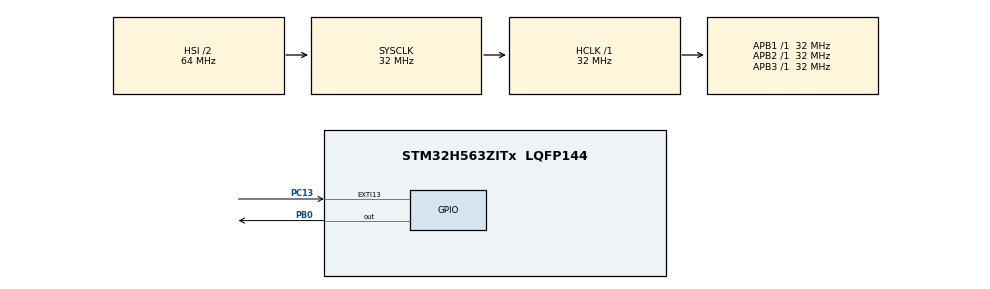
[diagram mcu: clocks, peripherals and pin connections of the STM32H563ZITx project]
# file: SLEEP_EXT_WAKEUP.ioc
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CORTEX_M33_NS.userName=CORTEX_M33
Mcu.Family=STM32H5
Mcu.Name=STM32H563ZITx
Mcu.Package=LQFP144
NVIC.EXTI13_IRQn=true\:0\:0\:false\:false\:true\:true\:true\:true
NVIC.PriorityGroup=NVIC_PRIORITYGROUP_4
NVIC.TIM3_IRQn=true\:0\:0\:false\:false\:true\:true\:true\:true
PB0.Signal=GPIO_Output
PC13.Signal=GPXTI13
PH0-OSC_IN(PH0).Mode=HSE-External-Oscillator
PH0-OSC_IN(PH0).Signal=RCC_OSC_IN
PH1-OSC_OUT(PH1).Mode=HSE-External-Oscillator
PH1-OSC_OUT(PH1).Signal=RCC_OSC_OUT
ProjectManager.HeapSize=0x200
ProjectManager.StackSize=0x400
ProjectManager.TargetToolchain=STM32CubeIDE
RCC.ADCFreq_Value=32000000
RCC.AHBFreq_Value=32000000
RCC.APB1Freq_Value=32000000
RCC.APB1TimFreq_Value=32000000
RCC.APB2Freq_Value=32000000
RCC.APB2TimFreq_Value=32000000
RCC.APB3Freq_Value=32000000
RCC.CSI_VALUE=4000000
RCC.CortexFreq_Value=32000000
RCC.EPOD_VALUE=4000000
RCC.HCLKFreq_Value=32000000
RCC.HSE_VALUE=25000000
RCC.HSI48_VALUE=48000000
RCC.HSI_VALUE=64000000
RCC.LSE_VALUE=32768
RCC.LSIRC_VALUE=32000
RCC.PLL2FRACN=0
RCC.PLL3FRACN=0
RCC.PLLFRACN=0
RCC.SYSCLKFreq_VALUE=32000000
RCC.USBFreq_Value=48000000
RCC.VCOOutputFreq_Value=516000000
VP_BOOTPATH_VS_BOOTPATH.Mode=BP_Activate
VP_CORTEX_M33_NS_VS_Hclk.Mode=Hclk_Mode
VP_MEMORYMAP_VS_MEMORYMAP.Mode=CurAppReg
VP_PWR_VS_DBSignals.Mode=DisableDeadBatterySignals
VP_PWR_VS_LPOM.Mode=PowerOptimisation
VP_PWR_VS_SECSignals.Mode=Security/Privilege
VP_TIM3_VS_ClockSourceINT.Mode=Internal
board=custom

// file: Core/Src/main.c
/* USER CODE BEGIN Header */
/**
  ******************************************************************************
  * @file           : main.c
  * @brief          : Main program body
  ******************************************************************************
  * @attention
  *
  * Copyright (c) 2024 STMicroelectronics.
  * All rights reserved.
  *
  * This software is licensed under terms that can be found in the LICENSE file
  * in the root directory of this software component.
  * If no LICENSE file comes with this software, it is provided AS-IS.
  *
  ******************************************************************************
  */
/* USER CODE END Header */
#include "main.h"

TIM_HandleTypeDef htim3;

/* USER CODE BEGIN PV */
uint8_t count =0;
/* USER CODE END PV */

void SystemClock_Config(void);
static void MX_GPIO_Init(void);
static void MX_TIM3_Init(void);

int main(void)
{

  /* MCU Configuration--------------------------------------------------------*/

  /* Reset of all peripherals, Initializes the Flash interface and the Systick. */
  HAL_Init();

  /* Configure the system clock */
  SystemClock_Config();

  /* Initialize all configured peripherals */
  MX_GPIO_Init();
  MX_TIM3_Init();

  /* Infinite loop */
  /* USER CODE BEGIN WHILE */
  while (1)

  {
	  if(count == 600)//60*10 10 minutes of inactivity counter
	  {
		  HAL_SuspendTick();// suspending systick clock before sleep low power

		  HAL_PWR_EnableSleepOnExit ();
		  //sleep mode
		  HAL_PWR_EnterSLEEPMode(PWR_MAINREGULATOR_ON, PWR_SLEEPENTRY_WFI);//entering sleep mode with wake up on external interrupt.

	  }
    /* USER CODE END WHILE */

  }
}

void SystemClock_Config(void)
{
  RCC_OscInitTypeDef RCC_OscInitStruct = {0};
  RCC_ClkInitTypeDef RCC_ClkInitStruct = {0};

  /** Configure the main internal regulator output voltage
  */
  __HAL_PWR_VOLTAGESCALING_CONFIG(PWR_REGULATOR_VOLTAGE_SCALE3);

  while(!__HAL_PWR_GET_FLAG(PWR_FLAG_VOSRDY)) {}

  /** Initializes the RCC Oscillators according to the specified parameters
  * in the RCC_OscInitTypeDef structure.
  */
  RCC_OscInitStruct.OscillatorType = RCC_OSCILLATORTYPE_HSI;
  RCC_OscInitStruct.HSIState = RCC_HSI_ON;
  RCC_OscInitStruct.HSIDiv = RCC_HSI_DIV2;
  RCC_OscInitStruct.HSICalibrationValue = RCC_HSICALIBRATION_DEFAULT;
  RCC_OscInitStruct.PLL.PLLState = RCC_PLL_NONE;
  if (HAL_RCC_OscConfig(&RCC_OscInitStruct) != HAL_OK)
  {
    Error_Handler();
  }

  /** Initializes the CPU, AHB and APB buses clocks
  */
  RCC_ClkInitStruct.ClockType = RCC_CLOCKTYPE_HCLK|RCC_CLOCKTYPE_SYSCLK
                              |RCC_CLOCKTYPE_PCLK1|RCC_CLOCKTYPE_PCLK2
                              |RCC_CLOCKTYPE_PCLK3;
  RCC_ClkInitStruct.SYSCLKSource = RCC_SYSCLKSOURCE_HSI;
  RCC_ClkInitStruct.AHBCLKDivider = RCC_SYSCLK_DIV1;
  RCC_ClkInitStruct.APB1CLKDivider = RCC_HCLK_DIV1;
  RCC_ClkInitStruct.APB2CLKDivider = RCC_HCLK_DIV1;
  RCC_ClkInitStruct.APB3CLKDivider = RCC_HCLK_DIV1;

  if (HAL_RCC_ClockConfig(&RCC_ClkInitStruct, FLASH_LATENCY_1) != HAL_OK)
  {
    Error_Handler();
  }

  /** Configure the programming delay
  */
  __HAL_FLASH_SET_PROGRAM_DELAY(FLASH_PROGRAMMING_DELAY_0);
}

static void MX_TIM3_Init(void)
{

  TIM_ClockConfigTypeDef sClockSourceConfig = {0};
  TIM_MasterConfigTypeDef sMasterConfig = {0};

  htim3.Instance = TIM3;
  htim3.Init.Prescaler = 10000;
  htim3.Init.CounterMode = TIM_COUNTERMODE_UP;
  htim3.Init.Period = 24999;//adjusted to give interupt every 1 sec
  htim3.Init.ClockDivision = TIM_CLOCKDIVISION_DIV1;
  htim3.Init.AutoReloadPreload = TIM_AUTORELOAD_PRELOAD_DISABLE;
  if (HAL_TIM_Base_Init(&htim3) != HAL_OK)
  {
  count++;
    Error_Handler();
  }
  sClockSourceConfig.ClockSource = TIM_CLOCKSOURCE_INTERNAL;
  if (HAL_TIM_ConfigClockSource(&htim3, &sClockSourceConfig) != HAL_OK)
  {
    Error_Handler();
  }
  sMasterConfig.MasterOutputTrigger = TIM_TRGO_RESET;
  sMasterConfig.MasterSlaveMode = TIM_MASTERSLAVEMODE_DISABLE;
  if (HAL_TIMEx_MasterConfigSynchronization(&htim3, &sMasterConfig) != HAL_OK)
  {
    Error_Handler();
  }

}

static void MX_GPIO_Init(void)
{
  GPIO_InitTypeDef GPIO_InitStruct = {0};

  /* GPIO Ports Clock Enable */
  __HAL_RCC_GPIOC_CLK_ENABLE();
  __HAL_RCC_GPIOH_CLK_ENABLE();
  __HAL_RCC_GPIOB_CLK_ENABLE();

  /*Configure GPIO pin Output Level */
  HAL_GPIO_WritePin(GPIOB, GPIO_PIN_0, GPIO_PIN_RESET);

  /*Configure GPIO pin : PC13 */
  GPIO_InitStruct.Pin = GPIO_PIN_13;
  GPIO_InitStruct.Mode = GPIO_MODE_IT_RISING;
  GPIO_InitStruct.Pull = GPIO_NOPULL;
  HAL_GPIO_Init(GPIOC, &GPIO_InitStruct);

  /*Configure GPIO pin : PB0 */
  GPIO_InitStruct.Pin = GPIO_PIN_0;
  GPIO_InitStruct.Mode = GPIO_MODE_OUTPUT_PP;
  GPIO_InitStruct.Pull = GPIO_NOPULL;
  GPIO_InitStruct.Speed = GPIO_SPEED_FREQ_LOW;
  HAL_GPIO_Init(GPIOB, &GPIO_InitStruct);

  /* EXTI interrupt init*/
  HAL_NVIC_SetPriority(EXTI13_IRQn, 0, 0);
  HAL_NVIC_EnableIRQ(EXTI13_IRQn);

}

/* USER CODE BEGIN 4 */
void HAL_GPIO_EXTI_Rising_Callback(uint16_t GPIO_Pin)
{
	if(GPIO_Pin == GPIO_PIN_13)
	{
		HAL_GPIO_WritePin(GPIOB,GPIO_PIN_0,1);//led ON to indicate external interrupt

		 HAL_ResumeTick();//waking up from the sleep mode resume to the routine
	}

}
/* USER CODE END 4 */

void Error_Handler(void)
{
  __disable_irq();
  while (1)
  {
  }
}
